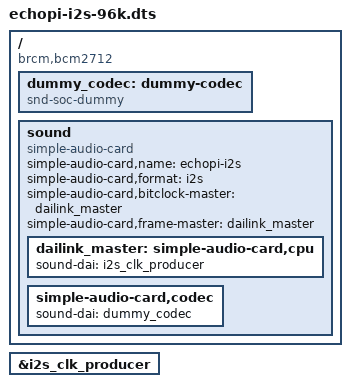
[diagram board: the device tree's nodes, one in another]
/*
 * Device Tree Overlay for bidirectional (full-duplex) I2S
 * Target: Raspberry Pi 5 (RP1) with I2S clock producer (Pi is BCLK/LRCLK master)
 * External devices: MAX98357A (playback) + INMP441 (capture)
 *
 * Note:
 * - These devices don't require I2C control.
 * - We use snd-soc-dummy as a codec endpoint; the RP1 I2S controller drives pins.
 */

/dts-v1/;
/plugin/;

/ {
    compatible = "brcm,bcm2712", "brcm,bcm2835";

    fragment@0 {
        target-path = "/";
        __overlay__ {
            dummy_codec: dummy-codec {
                #sound-dai-cells = <0>;
                compatible = "snd-soc-dummy";
                status = "okay";
            };
        };
    };

    fragment@1 {
        target = <&i2s_clk_producer>;
        __overlay__ {
            status = "okay";
        };
    };

    fragment@2 {
        target-path = "/";
        __overlay__ {
            sound {
                compatible = "simple-audio-card";
                simple-audio-card,name = "echopi-i2s";
                status = "okay";

                simple-audio-card,format = "i2s";
                simple-audio-card,bitclock-master = <&dailink_master>;
                simple-audio-card,frame-master = <&dailink_master>;

                dailink_master: simple-audio-card,cpu {
                    sound-dai = <&i2s_clk_producer>;
                };

                simple-audio-card,codec {
                    sound-dai = <&dummy_codec>;
                };
            };
        };
    };
};
